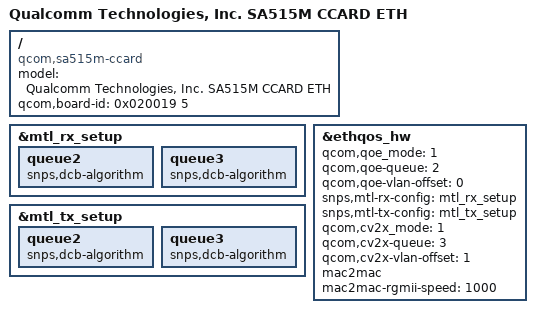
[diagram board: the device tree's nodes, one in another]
/dts-v1/;

#include "sa515m.dtsi"
#include "sa515m-ccard.dtsi"

/ {
	model = "Qualcomm Technologies, Inc. SA515M CCARD ETH";
	compatible = "qcom,sa515m-ccard",
			"qcom,sa515m", "qcom,ccard";
	qcom,board-id = <0x020019 5>;
};

&mtl_rx_setup {
	queue2 {
		snps,dcb-algorithm;
	};

	queue3 {
		snps,dcb-algorithm;
	};
};

&mtl_tx_setup {
	queue2 {
		snps,dcb-algorithm;
	};

	queue3 {
		snps,dcb-algorithm;
	};
};

&ethqos_hw {
	qcom,qoe_mode = <1>;
	qcom,qoe-queue = <2>;
	qcom,qoe-vlan-offset = <0>;
	snps,mtl-rx-config = <&mtl_rx_setup>;
	snps,mtl-tx-config = <&mtl_tx_setup>;
	qcom,cv2x_mode = <1>;
	qcom,cv2x-queue = <3>;
	qcom,cv2x-vlan-offset = <1>;
	mac2mac;
	mac2mac-rgmii-speed = <1000>;
};

